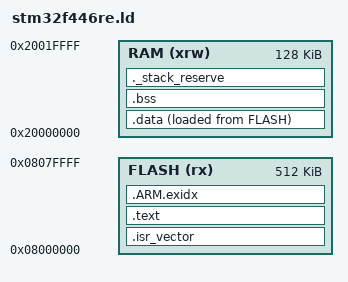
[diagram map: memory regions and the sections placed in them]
/*
 * Linker script for STM32F446RE (512 KB flash, 128 KB SRAM).
 */
ENTRY(Reset_Handler)

MEMORY
{
    FLASH (rx)  : ORIGIN = 0x08000000, LENGTH = 512K
    RAM   (xrw) : ORIGIN = 0x20000000, LENGTH = 128K
}

/* Initial main stack pointer: top of RAM. */
_estack = ORIGIN(RAM) + LENGTH(RAM);

/* Main stack is only used before the scheduler starts and by interrupts. */
_Min_Stack_Size = 0x800;

SECTIONS
{
    .isr_vector :
    {
        . = ALIGN(4);
        KEEP(*(.isr_vector))
        . = ALIGN(4);
    } > FLASH

    .text :
    {
        . = ALIGN(4);
        *(.text)
        *(.text*)
        *(.rodata)
        *(.rodata*)
        KEEP(*(.init))
        KEEP(*(.fini))
        . = ALIGN(4);
        _etext = .;
    } > FLASH

    .ARM.exidx :
    {
        *(.ARM.exidx*)
    } > FLASH

    _sidata = LOADADDR(.data);

    .data :
    {
        . = ALIGN(4);
        _sdata = .;
        *(.data)
        *(.data*)
        . = ALIGN(4);
        _edata = .;
    } > RAM AT > FLASH

    .bss (NOLOAD) :
    {
        . = ALIGN(4);
        _sbss = .;
        *(.bss)
        *(.bss*)
        *(COMMON)
        . = ALIGN(4);
        _ebss = .;
    } > RAM

    /* Reserve room for the main stack; fails to link if RAM is full. */
    ._stack_reserve (NOLOAD) :
    {
        . = ALIGN(8);
        PROVIDE(end = .);
        PROVIDE(_end = .);
        . = . + _Min_Stack_Size;
        . = ALIGN(8);
    } > RAM

    .ARM.attributes 0 : { *(.ARM.attributes) }
}
